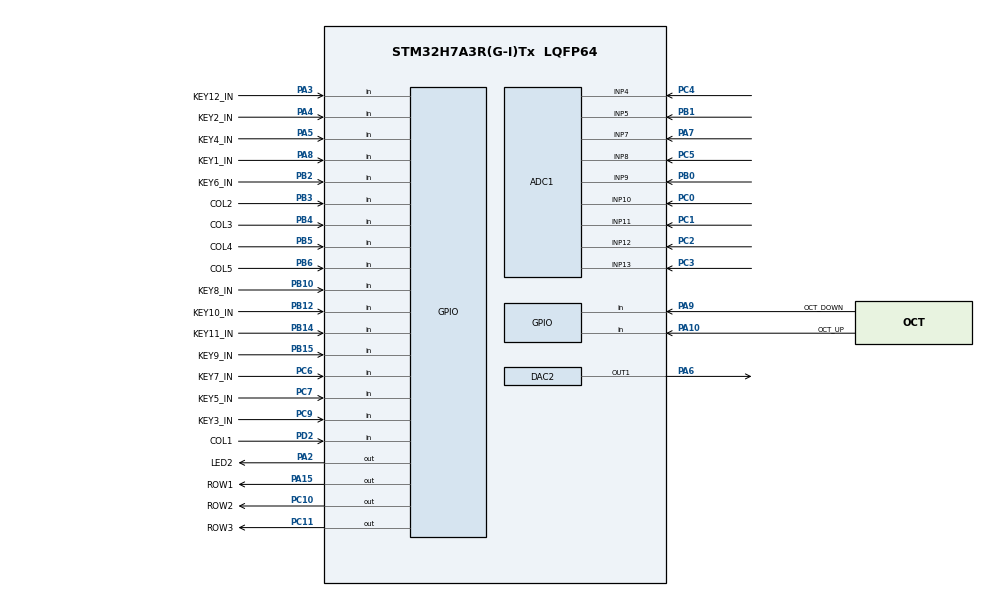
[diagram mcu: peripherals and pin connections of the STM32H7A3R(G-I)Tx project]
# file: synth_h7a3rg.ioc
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ADC1.Channel-1\#ChannelRegularConversion=ADC_CHANNEL_4
ADC1.NbrOfConversionFlag=1
ADC1.OffsetNumber-1\#ChannelRegularConversion=ADC_OFFSET_NONE
ADC1.OffsetSignedSaturation-1\#ChannelRegularConversion=DISABLE
ADC1.Rank-1\#ChannelRegularConversion=1
ADC1.SamplingTime-1\#ChannelRegularConversion=ADC_SAMPLETIME_1CYCLE_5
ADC1.master=1
CORTEX_M7.default_mode_Activation=1
DAC2.DAC_Channel-DAC_OUT1=DAC_CHANNEL_1
Mcu.Family=STM32H7
Mcu.Name=STM32H7A3R(G-I)Tx
Mcu.Package=LQFP64
NVIC.PriorityGroup=NVIC_PRIORITYGROUP_4
NVIC.TIM1_UP_IRQn=true\:0\:0\:false\:false\:true\:true\:true\:true
NVIC.TIM2_IRQn=true\:1\:0\:true\:false\:true\:true\:true\:true
NVIC.TIM3_IRQn=true\:1\:0\:true\:false\:true\:true\:true\:true
PA10.GPIO_Label=OCT_UP
PA10.GPIO_PuPd=GPIO_PULLUP
PA10.Signal=GPIO_Input
PA15.GPIO_Label=ROW1
PA15.Signal=GPIO_Output
PA2.GPIO_Label=LED2
PA2.Signal=GPIO_Output
PA3.GPIO_Label=KEY12_IN
PA3.GPIO_PuPd=GPIO_PULLUP
PA3.Signal=GPIO_Input
PA4.GPIO_Label=KEY2_IN
PA4.GPIO_PuPd=GPIO_PULLUP
PA4.Signal=GPIO_Input
PA5.GPIO_Label=KEY4_IN
PA5.GPIO_PuPd=GPIO_PULLUP
PA5.Signal=GPIO_Input
PA6.Signal=COMP_DAC21_group
PA7.Signal=ADCx_INP7
PA8.GPIO_Label=KEY1_IN
PA8.GPIO_PuPd=GPIO_PULLUP
PA8.Signal=GPIO_Input
PA9.GPIO_Label=OCT_DOWN
PA9.GPIO_PuPd=GPIO_PULLUP
PA9.Signal=GPIO_Input
PB0.Signal=ADCx_INP9
PB1.Signal=ADCx_INP5
PB10.GPIO_Label=KEY8_IN
PB10.GPIO_PuPd=GPIO_PULLUP
PB10.Signal=GPIO_Input
PB12.GPIO_Label=KEY10_IN
PB12.GPIO_PuPd=GPIO_PULLUP
PB12.Signal=GPIO_Input
PB14.GPIO_Label=KEY11_IN
PB14.GPIO_PuPd=GPIO_PULLUP
PB14.Signal=GPIO_Input
PB15.GPIO_Label=KEY9_IN
PB15.GPIO_PuPd=GPIO_PULLUP
PB15.Signal=GPIO_Input
PB2.GPIO_Label=KEY6_IN
PB2.GPIO_PuPd=GPIO_PULLUP
PB2.Signal=GPIO_Input
PB3.GPIO_Label=COL2
PB3.GPIO_PuPd=GPIO_PULLUP
PB3.Signal=GPIO_Input
PB4.GPIO_Label=COL3
PB4.GPIO_PuPd=GPIO_PULLUP
PB4.Signal=GPIO_Input
PB5.GPIO_Label=COL4
PB5.GPIO_PuPd=GPIO_PULLUP
PB5.Signal=GPIO_Input
PB6.GPIO_Label=COL5
PB6.GPIO_PuPd=GPIO_PULLUP
PB6.Signal=GPIO_Input
PC0.Signal=ADCx_INP10
PC1.Signal=ADCx_INP11
PC10.GPIO_Label=ROW2
PC10.Signal=GPIO_Output
PC11.GPIO_Label=ROW3
PC11.Signal=GPIO_Output
PC2.Signal=ADCx_INP12
PC3.Signal=ADCx_INP13
PC4.Signal=ADCx_INP4
PC5.Signal=ADCx_INP8
PC6.GPIO_Label=KEY7_IN
PC6.GPIO_PuPd=GPIO_PULLUP
PC6.Signal=GPIO_Input
PC7.GPIO_Label=KEY5_IN
PC7.GPIO_PuPd=GPIO_PULLUP
PC7.Signal=GPIO_Input
PC9.GPIO_Label=KEY3_IN
PC9.GPIO_PuPd=GPIO_PULLUP
PC9.Signal=GPIO_Input
PD2.GPIO_Label=COL1
PD2.GPIO_PuPd=GPIO_PULLUP
PD2.Signal=GPIO_Input
ProjectManager.HeapSize=0x000
ProjectManager.StackSize=0x400
ProjectManager.TargetToolchain=CMake
RCC.ADCFreq_Value=42666666.666666664
RCC.APB1Freq_Value=140000000
RCC.APB2Freq_Value=140000000
RCC.APB3Freq_Value=140000000
RCC.APB4Freq_Value=140000000
RCC.CDPPRE=RCC_APB3_DIV2
RCC.CDPPRE1=RCC_APB1_DIV2
RCC.CDPPRE2=RCC_APB2_DIV2
RCC.CortexFreq_Value=280000000
RCC.DIVM1=4
RCC.DIVM2=4
RCC.DIVN1=35
RCC.DIVN2=8
RCC.DIVP2=3
RCC.HCLKFreq_Value=280000000
RCC.LockedElements=CDCPREOutput
RCC.PLL2FRACN=0
RCC.PLL3FRACN=0
RCC.PLLFRACN=0
RCC.SRDPPRE=RCC_APB4_DIV2
RCC.SYSCLKFreq_VALUE=280000000
RCC.SYSCLKSource=RCC_SYSCLKSOURCE_PLLCLK
RCC.USBFreq_Value=280000000
SH.ADCx_INP10.0=ADC1_INP10,IN10-Single-Ended
SH.ADCx_INP11.0=ADC1_INP11,IN11-Single-Ended
SH.ADCx_INP12.0=ADC1_INP12,IN12-Single-Ended
SH.ADCx_INP13.0=ADC1_INP13,IN13-Single-Ended
SH.ADCx_INP4.0=ADC1_INP4,IN4-Single-Ended
SH.ADCx_INP5.0=ADC1_INP5,IN5-Single-Ended
SH.ADCx_INP7.0=ADC1_INP7,IN7-Single-Ended
SH.ADCx_INP8.0=ADC1_INP8,IN8-Single-Ended
SH.ADCx_INP9.0=ADC1_INP9,IN9-Single-Ended
SH.COMP_DAC21_group.0=DAC2_OUT1,DAC_OUT1
TIM1.AutoReloadPreload=TIM_AUTORELOAD_PRELOAD_DISABLE
TIM1.Period=10000
TIM1.Prescaler=0
TIM2.Period=10000
TIM2.Prescaler=500
TIM3.Period=10000
TIM3.Prescaler=1000
VP_MEMORYMAP_VS_MEMORYMAP.Mode=CurAppReg
VP_TIM1_VS_ClockSourceINT.Mode=Internal
VP_TIM1_VS_ClockSourceITR.Mode=TriggerSource_ITR0
VP_TIM2_VS_ClockSourceINT.Mode=Internal
VP_TIM2_VS_ClockSourceITR.Mode=TriggerSource_ITR1
VP_TIM3_VS_ClockSourceINT.Mode=Internal
VP_TIM3_VS_ClockSourceITR.Mode=TriggerSource_ITR2
board=custom

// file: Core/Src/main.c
/* USER CODE BEGIN Header */
/**
  ******************************************************************************
  * @file           : main.c
  * @brief          : Main program body
  ******************************************************************************
  * @attention
  *
  * Copyright (c) 2026 STMicroelectronics.
  * All rights reserved.
  *
  * This software is licensed under terms that can be found in the LICENSE file
  * in the root directory of this software component.
  * If no LICENSE file comes with this software, it is provided AS-IS.
  *
  ******************************************************************************
  */
/* USER CODE END Header */
#include "main.h"

/* USER CODE BEGIN Includes */
#include "pmain.h"
/* USER CODE END Includes */

ADC_HandleTypeDef hadc1;

DAC_HandleTypeDef hdac2;

TIM_HandleTypeDef htim1;
TIM_HandleTypeDef htim2;
TIM_HandleTypeDef htim3;

void SystemClock_Config(void);
static void MPU_Config(void);
static void MX_GPIO_Init(void);
static void MX_ADC1_Init(void);
static void MX_DAC2_Init(void);
static void MX_TIM1_Init(void);
static void MX_TIM2_Init(void);
static void MX_TIM3_Init(void);

int main(void)
{

  /* MPU Configuration--------------------------------------------------------*/
  MPU_Config();

  /* MCU Configuration--------------------------------------------------------*/

  /* Reset of all peripherals, Initializes the Flash interface and the Systick. */
  HAL_Init();

  /* Configure the system clock */
  SystemClock_Config();

  /* Initialize all configured peripherals */
  MX_GPIO_Init();
  MX_ADC1_Init();
  MX_DAC2_Init();
  MX_TIM1_Init();
  MX_TIM2_Init();
  MX_TIM3_Init();
  /* USER CODE BEGIN 2 */
  pmain();
  /* USER CODE END 2 */

  /* Infinite loop */
  while (1)
  {

  }
}

void SystemClock_Config(void)
{
  RCC_OscInitTypeDef RCC_OscInitStruct = {0};
  RCC_ClkInitTypeDef RCC_ClkInitStruct = {0};

  /*AXI clock gating */
  RCC->CKGAENR = 0xE003FFFF;

  /** Supply configuration update enable
  */
  HAL_PWREx_ConfigSupply(PWR_LDO_SUPPLY);

  /** Configure the main internal regulator output voltage
  */
  __HAL_PWR_VOLTAGESCALING_CONFIG(PWR_REGULATOR_VOLTAGE_SCALE0);

  while(!__HAL_PWR_GET_FLAG(PWR_FLAG_VOSRDY)) {}

  /** Initializes the RCC Oscillators according to the specified parameters
  * in the RCC_OscInitTypeDef structure.
  */
  RCC_OscInitStruct.OscillatorType = RCC_OSCILLATORTYPE_HSI|RCC_OSCILLATORTYPE_LSI;
  RCC_OscInitStruct.HSIState = RCC_HSI_DIV1;
  RCC_OscInitStruct.HSICalibrationValue = 64;
  RCC_OscInitStruct.LSIState = RCC_LSI_ON;
  RCC_OscInitStruct.PLL.PLLState = RCC_PLL_ON;
  RCC_OscInitStruct.PLL.PLLSource = RCC_PLLSOURCE_HSI;
  RCC_OscInitStruct.PLL.PLLM = 4;
  RCC_OscInitStruct.PLL.PLLN = 35;
  RCC_OscInitStruct.PLL.PLLP = 2;
  RCC_OscInitStruct.PLL.PLLQ = 2;
  RCC_OscInitStruct.PLL.PLLR = 2;
  RCC_OscInitStruct.PLL.PLLRGE = RCC_PLL1VCIRANGE_3;
  RCC_OscInitStruct.PLL.PLLVCOSEL = RCC_PLL1VCOWIDE;
  RCC_OscInitStruct.PLL.PLLFRACN = 0;
  if (HAL_RCC_OscConfig(&RCC_OscInitStruct) != HAL_OK)
  {
    Error_Handler();
  }

  /** Initializes the CPU, AHB and APB buses clocks
  */
  RCC_ClkInitStruct.ClockType = RCC_CLOCKTYPE_HCLK|RCC_CLOCKTYPE_SYSCLK
                              |RCC_CLOCKTYPE_PCLK1|RCC_CLOCKTYPE_PCLK2
                              |RCC_CLOCKTYPE_D3PCLK1|RCC_CLOCKTYPE_D1PCLK1;
  RCC_ClkInitStruct.SYSCLKSource = RCC_SYSCLKSOURCE_PLLCLK;
  RCC_ClkInitStruct.SYSCLKDivider = RCC_SYSCLK_DIV1;
  RCC_ClkInitStruct.AHBCLKDivider = RCC_HCLK_DIV1;
  RCC_ClkInitStruct.APB3CLKDivider = RCC_APB3_DIV2;
  RCC_ClkInitStruct.APB1CLKDivider = RCC_APB1_DIV2;
  RCC_ClkInitStruct.APB2CLKDivider = RCC_APB2_DIV2;
  RCC_ClkInitStruct.APB4CLKDivider = RCC_APB4_DIV2;

  if (HAL_RCC_ClockConfig(&RCC_ClkInitStruct, FLASH_LATENCY_6) != HAL_OK)
  {
    Error_Handler();
  }
}

static void MX_ADC1_Init(void)
{

  ADC_MultiModeTypeDef multimode = {0};
  ADC_ChannelConfTypeDef sConfig = {0};

  /** Common config
  */
  hadc1.Instance = ADC1;
  hadc1.Init.ClockPrescaler = ADC_CLOCK_ASYNC_DIV1;
  hadc1.Init.Resolution = ADC_RESOLUTION_16B;
  hadc1.Init.ScanConvMode = ADC_SCAN_DISABLE;
  hadc1.Init.EOCSelection = ADC_EOC_SINGLE_CONV;
  hadc1.Init.LowPowerAutoWait = DISABLE;
  hadc1.Init.ContinuousConvMode = DISABLE;
  hadc1.Init.NbrOfConversion = 1;
  hadc1.Init.DiscontinuousConvMode = DISABLE;
  hadc1.Init.ExternalTrigConv = ADC_SOFTWARE_START;
  hadc1.Init.ExternalTrigConvEdge = ADC_EXTERNALTRIGCONVEDGE_NONE;
  hadc1.Init.ConversionDataManagement = ADC_CONVERSIONDATA_DR;
  hadc1.Init.Overrun = ADC_OVR_DATA_PRESERVED;
  hadc1.Init.LeftBitShift = ADC_LEFTBITSHIFT_NONE;
  hadc1.Init.OversamplingMode = DISABLE;
  if (HAL_ADC_Init(&hadc1) != HAL_OK)
  {
    Error_Handler();
  }

  /** Configure the ADC multi-mode
  */
  multimode.Mode = ADC_MODE_INDEPENDENT;
  if (HAL_ADCEx_MultiModeConfigChannel(&hadc1, &multimode) != HAL_OK)
  {
    Error_Handler();
  }

  /** Configure Regular Channel
  */
  sConfig.Channel = ADC_CHANNEL_4;
  sConfig.Rank = ADC_REGULAR_RANK_1;
  sConfig.SamplingTime = ADC_SAMPLETIME_1CYCLE_5;
  sConfig.SingleDiff = ADC_SINGLE_ENDED;
  sConfig.OffsetNumber = ADC_OFFSET_NONE;
  sConfig.Offset = 0;
  sConfig.OffsetSignedSaturation = DISABLE;
  if (HAL_ADC_ConfigChannel(&hadc1, &sConfig) != HAL_OK)
  {
    Error_Handler();
  }

}

static void MX_DAC2_Init(void)
{

  DAC_ChannelConfTypeDef sConfig = {0};

  /** DAC Initialization
  */
  hdac2.Instance = DAC2;
  if (HAL_DAC_Init(&hdac2) != HAL_OK)
  {
    Error_Handler();
  }

  /** DAC channel OUT1 config
  */
  sConfig.DAC_SampleAndHold = DAC_SAMPLEANDHOLD_DISABLE;
  sConfig.DAC_Trigger = DAC_TRIGGER_NONE;
  sConfig.DAC_OutputBuffer = DAC_OUTPUTBUFFER_ENABLE;
  sConfig.DAC_ConnectOnChipPeripheral = DAC_CHIPCONNECT_DISABLE;
  sConfig.DAC_UserTrimming = DAC_TRIMMING_FACTORY;
  if (HAL_DAC_ConfigChannel(&hdac2, &sConfig, DAC_CHANNEL_1) != HAL_OK)
  {
    Error_Handler();
  }

}

static void MX_TIM1_Init(void)
{

  TIM_ClockConfigTypeDef sClockSourceConfig = {0};
  TIM_SlaveConfigTypeDef sSlaveConfig = {0};
  TIM_MasterConfigTypeDef sMasterConfig = {0};

  htim1.Instance = TIM1;
  htim1.Init.Prescaler = 0;
  htim1.Init.CounterMode = TIM_COUNTERMODE_UP;
  htim1.Init.Period = 10000;
  htim1.Init.ClockDivision = TIM_CLOCKDIVISION_DIV1;
  htim1.Init.RepetitionCounter = 0;
  htim1.Init.AutoReloadPreload = TIM_AUTORELOAD_PRELOAD_DISABLE;
  if (HAL_TIM_Base_Init(&htim1) != HAL_OK)
  {
    Error_Handler();
  }
  sClockSourceConfig.ClockSource = TIM_CLOCKSOURCE_INTERNAL;
  if (HAL_TIM_ConfigClockSource(&htim1, &sClockSourceConfig) != HAL_OK)
  {
    Error_Handler();
  }
  sSlaveConfig.SlaveMode = TIM_SLAVEMODE_DISABLE;
  sSlaveConfig.InputTrigger = TIM_TS_ITR0;
  if (HAL_TIM_SlaveConfigSynchro(&htim1, &sSlaveConfig) != HAL_OK)
  {
    Error_Handler();
  }
  sMasterConfig.MasterOutputTrigger = TIM_TRGO_RESET;
  sMasterConfig.MasterOutputTrigger2 = TIM_TRGO2_RESET;
  sMasterConfig.MasterSlaveMode = TIM_MASTERSLAVEMODE_DISABLE;
  if (HAL_TIMEx_MasterConfigSynchronization(&htim1, &sMasterConfig) != HAL_OK)
  {
    Error_Handler();
  }
  /* USER CODE BEGIN TIM1_Init 2 */
  HAL_TIM_Base_Start_IT(&htim1);
  /* USER CODE END TIM1_Init 2 */

}

static void MX_TIM2_Init(void)
{

  TIM_ClockConfigTypeDef sClockSourceConfig = {0};
  TIM_SlaveConfigTypeDef sSlaveConfig = {0};
  TIM_MasterConfigTypeDef sMasterConfig = {0};

  htim2.Instance = TIM2;
  htim2.Init.Prescaler = 500;
  htim2.Init.CounterMode = TIM_COUNTERMODE_UP;
  htim2.Init.Period = 10000;
  htim2.Init.ClockDivision = TIM_CLOCKDIVISION_DIV1;
  htim2.Init.AutoReloadPreload = TIM_AUTORELOAD_PRELOAD_DISABLE;
  if (HAL_TIM_Base_Init(&htim2) != HAL_OK)
  {
    Error_Handler();
  }
  sClockSourceConfig.ClockSource = TIM_CLOCKSOURCE_INTERNAL;
  if (HAL_TIM_ConfigClockSource(&htim2, &sClockSourceConfig) != HAL_OK)
  {
    Error_Handler();
  }
  sSlaveConfig.SlaveMode = TIM_SLAVEMODE_DISABLE;
  sSlaveConfig.InputTrigger = TIM_TS_ITR1;
  if (HAL_TIM_SlaveConfigSynchro(&htim2, &sSlaveConfig) != HAL_OK)
  {
    Error_Handler();
  }
  sMasterConfig.MasterOutputTrigger = TIM_TRGO_RESET;
  sMasterConfig.MasterSlaveMode = TIM_MASTERSLAVEMODE_DISABLE;
  if (HAL_TIMEx_MasterConfigSynchronization(&htim2, &sMasterConfig) != HAL_OK)
  {
    Error_Handler();
  }

}

static void MX_TIM3_Init(void)
{

  TIM_ClockConfigTypeDef sClockSourceConfig = {0};
  TIM_SlaveConfigTypeDef sSlaveConfig = {0};
  TIM_MasterConfigTypeDef sMasterConfig = {0};

  htim3.Instance = TIM3;
  htim3.Init.Prescaler = 1000;
  htim3.Init.CounterMode = TIM_COUNTERMODE_UP;
  htim3.Init.Period = 10000;
  htim3.Init.ClockDivision = TIM_CLOCKDIVISION_DIV1;
  htim3.Init.AutoReloadPreload = TIM_AUTORELOAD_PRELOAD_DISABLE;
  if (HAL_TIM_Base_Init(&htim3) != HAL_OK)
  {
    Error_Handler();
  }
  sClockSourceConfig.ClockSource = TIM_CLOCKSOURCE_INTERNAL;
  if (HAL_TIM_ConfigClockSource(&htim3, &sClockSourceConfig) != HAL_OK)
  {
    Error_Handler();
  }
  sSlaveConfig.SlaveMode = TIM_SLAVEMODE_DISABLE;
  sSlaveConfig.InputTrigger = TIM_TS_ITR2;
  if (HAL_TIM_SlaveConfigSynchro(&htim3, &sSlaveConfig) != HAL_OK)
  {
    Error_Handler();
  }
  sMasterConfig.MasterOutputTrigger = TIM_TRGO_RESET;
  sMasterConfig.MasterSlaveMode = TIM_MASTERSLAVEMODE_DISABLE;
  if (HAL_TIMEx_MasterConfigSynchronization(&htim3, &sMasterConfig) != HAL_OK)
  {
    Error_Handler();
  }

}

static void MX_GPIO_Init(void)
{
  GPIO_InitTypeDef GPIO_InitStruct = {0};

  /* GPIO Ports Clock Enable */
  __HAL_RCC_GPIOC_CLK_ENABLE();
  __HAL_RCC_GPIOA_CLK_ENABLE();
  __HAL_RCC_GPIOB_CLK_ENABLE();
  __HAL_RCC_GPIOD_CLK_ENABLE();

  /*Configure GPIO pin Output Level */
  HAL_GPIO_WritePin(GPIOA, LED2_Pin|ROW1_Pin, GPIO_PIN_RESET);

  /*Configure GPIO pin Output Level */
  HAL_GPIO_WritePin(GPIOC, ROW2_Pin|ROW3_Pin, GPIO_PIN_RESET);

  /*Configure GPIO pins : LED2_Pin ROW1_Pin */
  GPIO_InitStruct.Pin = LED2_Pin|ROW1_Pin;
  GPIO_InitStruct.Mode = GPIO_MODE_OUTPUT_PP;
  GPIO_InitStruct.Pull = GPIO_NOPULL;
  GPIO_InitStruct.Speed = GPIO_SPEED_FREQ_LOW;
  HAL_GPIO_Init(GPIOA, &GPIO_InitStruct);

  /*Configure GPIO pins : KEY12_IN_Pin KEY2_IN_Pin KEY4_IN_Pin KEY1_IN_Pin
                           OCT_DOWN_Pin OCT_UP_Pin */
  GPIO_InitStruct.Pin = KEY12_IN_Pin|KEY2_IN_Pin|KEY4_IN_Pin|KEY1_IN_Pin
                          |OCT_DOWN_Pin|OCT_UP_Pin;
  GPIO_InitStruct.Mode = GPIO_MODE_INPUT;
  GPIO_InitStruct.Pull = GPIO_PULLUP;
  HAL_GPIO_Init(GPIOA, &GPIO_InitStruct);

  /*Configure GPIO pins : KEY6_IN_Pin KEY8_IN_Pin KEY10_IN_Pin KEY11_IN_Pin
                           KEY9_IN_Pin COL2_Pin COL3_Pin COL4_Pin
                           COL5_Pin */
  GPIO_InitStruct.Pin = KEY6_IN_Pin|KEY8_IN_Pin|KEY10_IN_Pin|KEY11_IN_Pin
                          |KEY9_IN_Pin|COL2_Pin|COL3_Pin|COL4_Pin
                          |COL5_Pin;
  GPIO_InitStruct.Mode = GPIO_MODE_INPUT;
  GPIO_InitStruct.Pull = GPIO_PULLUP;
  HAL_GPIO_Init(GPIOB, &GPIO_InitStruct);

  /*Configure GPIO pins : KEY7_IN_Pin KEY5_IN_Pin KEY3_IN_Pin */
  GPIO_InitStruct.Pin = KEY7_IN_Pin|KEY5_IN_Pin|KEY3_IN_Pin;
  GPIO_InitStruct.Mode = GPIO_MODE_INPUT;
  GPIO_InitStruct.Pull = GPIO_PULLUP;
  HAL_GPIO_Init(GPIOC, &GPIO_InitStruct);

  /*Configure GPIO pins : ROW2_Pin ROW3_Pin */
  GPIO_InitStruct.Pin = ROW2_Pin|ROW3_Pin;
  GPIO_InitStruct.Mode = GPIO_MODE_OUTPUT_PP;
  GPIO_InitStruct.Pull = GPIO_NOPULL;
  GPIO_InitStruct.Speed = GPIO_SPEED_FREQ_LOW;
  HAL_GPIO_Init(GPIOC, &GPIO_InitStruct);

  /*Configure GPIO pin : COL1_Pin */
  GPIO_InitStruct.Pin = COL1_Pin;
  GPIO_InitStruct.Mode = GPIO_MODE_INPUT;
  GPIO_InitStruct.Pull = GPIO_PULLUP;
  HAL_GPIO_Init(COL1_GPIO_Port, &GPIO_InitStruct);

}

 /* MPU Configuration */

void MPU_Config(void)
{
  MPU_Region_InitTypeDef MPU_InitStruct = {0};

  /* Disables the MPU */
  HAL_MPU_Disable();

  /** Initializes and configures the Region and the memory to be protected
  */
  MPU_InitStruct.Enable = MPU_REGION_ENABLE;
  MPU_InitStruct.Number = MPU_REGION_NUMBER0;
  MPU_InitStruct.BaseAddress = 0x0;
  MPU_InitStruct.Size = MPU_REGION_SIZE_4GB;
  MPU_InitStruct.SubRegionDisable = 0x87;
  MPU_InitStruct.TypeExtField = MPU_TEX_LEVEL0;
  MPU_InitStruct.AccessPermission = MPU_REGION_NO_ACCESS;
  MPU_InitStruct.DisableExec = MPU_INSTRUCTION_ACCESS_DISABLE;
  MPU_InitStruct.IsShareable = MPU_ACCESS_SHAREABLE;
  MPU_InitStruct.IsCacheable = MPU_ACCESS_NOT_CACHEABLE;
  MPU_InitStruct.IsBufferable = MPU_ACCESS_NOT_BUFFERABLE;

  HAL_MPU_ConfigRegion(&MPU_InitStruct);
  /* Enables the MPU */
  HAL_MPU_Enable(MPU_PRIVILEGED_DEFAULT);

}

void Error_Handler(void)
{
  __disable_irq();
  while (1)
  {
  }
}
